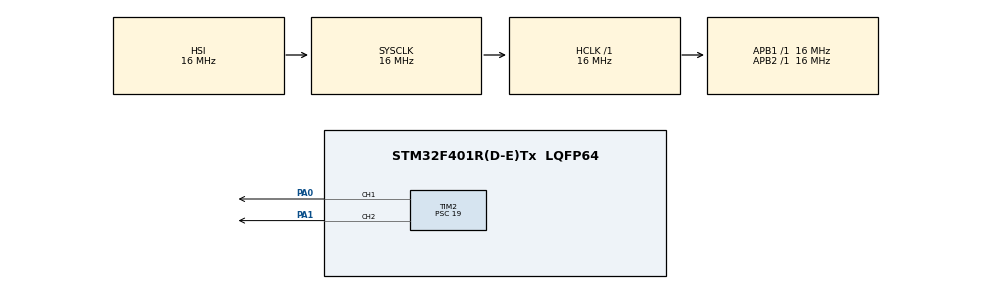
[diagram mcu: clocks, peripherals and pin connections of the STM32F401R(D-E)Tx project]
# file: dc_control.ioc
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Mcu.Family=STM32F4
Mcu.Name=STM32F401R(D-E)Tx
Mcu.Package=LQFP64
NVIC.PriorityGroup=NVIC_PRIORITYGROUP_4
NVIC.TIM2_IRQn=true\:0\:0\:false\:false\:true\:true\:true
PA0-WKUP.Signal=S_TIM2_CH1_ETR
PA1.Signal=S_TIM2_CH2
ProjectManager.HeapSize=0x200
ProjectManager.StackSize=0x400
ProjectManager.TargetToolchain=STM32CubeIDE
RCC.AHBFreq_Value=16000000
RCC.APB1Freq_Value=16000000
RCC.APB2Freq_Value=16000000
RCC.CortexFreq_Value=16000000
RCC.HSE_VALUE=25000000
RCC.HSI_VALUE=16000000
RCC.LSE_VALUE=32768
RCC.SYSCLKFreq_VALUE=16000000
RCC.VCOOutputFreq_Value=192000000
SH.S_TIM2_CH1_ETR.0=TIM2_CH1,PWM Generation1 CH1
SH.S_TIM2_CH2.0=TIM2_CH2,PWM Generation2 CH2
TIM2.Channel-PWM\ Generation1\ CH1=TIM_CHANNEL_1
TIM2.Channel-PWM\ Generation2\ CH2=TIM_CHANNEL_2
TIM2.Period=1000
TIM2.Prescaler=19
TIM2.Pulse-PWM\ Generation1\ CH1=500
TIM2.Pulse-PWM\ Generation2\ CH2=500
VP_TIM2_VS_ClockSourceINT.Mode=Internal
board=custom

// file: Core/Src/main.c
/* USER CODE BEGIN Header */
/**
  ******************************************************************************
  * @file           : main.c
  * @brief          : Main program body
  ******************************************************************************
  * @attention
  *
  * <h2><center>&copy; Copyright (c) 2021 STMicroelectronics.
  * All rights reserved.</center></h2>
  *
  * This software component is licensed by ST under BSD 3-Clause license,
  * the "License"; You may not use this file except in compliance with the
  * License. You may obtain a copy of the License at:
  *                        opensource.org/licenses/BSD-3-Clause
  *
  ******************************************************************************
  */
/* USER CODE END Header */
#include "main.h"

TIM_HandleTypeDef htim2;

void SystemClock_Config(void);
static void MX_GPIO_Init(void);
static void MX_TIM2_Init(void);

int main(void)
{

  /* MCU Configuration--------------------------------------------------------*/

  /* Reset of all peripherals, Initializes the Flash interface and the Systick. */
  HAL_Init();

  /* Configure the system clock */
  SystemClock_Config();

  /* Initialize all configured peripherals */
  MX_GPIO_Init();
  MX_TIM2_Init();
  /* USER CODE BEGIN 2 */
  HAL_TIM_Base_Start(&htim2);
  HAL_TIM_PWM_Start(&htim2,TIM_CHANNEL_1);  //PB0 Start pwm second motor 100% duty cycle
  HAL_TIM_PWM_Start(&htim2,TIM_CHANNEL_2);
  __HAL_TIM_SET_COMPARE(&htim2,TIM_CHANNEL_2,0);
  __HAL_TIM_SET_COMPARE(&htim2,TIM_CHANNEL_1,0);
  HAL_Delay(3000);
//  __HAL_TIM_SET_COMPARE(&htim2,TIM_CHANNEL_1,500);
//  HAL_Delay(3000);
//   /* USER CODE END 2 */
//   HAL_Delay(3000);
//   HAL_TIM_PWM_Stop(&htim2,TIM_CHANNEL_1);
//   __HAL_TIM_SET_COMPARE(&htim2,TIM_CHANNEL_1,500); //Second motor 75% voltage
//   HAL_Delay(3000);
//   HAL_TIM_PWM_Start(&htim2,TIM_CHANNEL_2);
//   HAL_Delay(3000);
//   __HAL_TIM_SET_COMPARE(&htim2,TIM_CHANNEL_2,500);
   //__HAL_TIM_SET_COMPARE(&htim3,TIM_CHANNEL_4,75);
  /* USER CODE END 2 */
 // int i = 100 ;
  /* Infinite loop */
  /* USER CODE BEGIN WHILE */
  while (1)
  {
	  __HAL_TIM_SET_COMPARE(&htim2,TIM_CHANNEL_1,500);
	  HAL_Delay(3000);
	  __HAL_TIM_SET_COMPARE(&htim2,TIM_CHANNEL_1,0);
	  __HAL_TIM_SET_COMPARE(&htim2,TIM_CHANNEL_2,500);
	  HAL_Delay(3000);
	  __HAL_TIM_SET_COMPARE(&htim2,TIM_CHANNEL_2,0);
    /* USER CODE END WHILE */

  }
}

void SystemClock_Config(void)
{
  RCC_OscInitTypeDef RCC_OscInitStruct = {0};
  RCC_ClkInitTypeDef RCC_ClkInitStruct = {0};

  /** Configure the main internal regulator output voltage
  */
  __HAL_RCC_PWR_CLK_ENABLE();
  __HAL_PWR_VOLTAGESCALING_CONFIG(PWR_REGULATOR_VOLTAGE_SCALE2);
  /** Initializes the RCC Oscillators according to the specified parameters
  * in the RCC_OscInitTypeDef structure.
  */
  RCC_OscInitStruct.OscillatorType = RCC_OSCILLATORTYPE_HSI;
  RCC_OscInitStruct.HSIState = RCC_HSI_ON;
  RCC_OscInitStruct.HSICalibrationValue = RCC_HSICALIBRATION_DEFAULT;
  RCC_OscInitStruct.PLL.PLLState = RCC_PLL_NONE;
  if (HAL_RCC_OscConfig(&RCC_OscInitStruct) != HAL_OK)
  {
    Error_Handler();
  }
  /** Initializes the CPU, AHB and APB buses clocks
  */
  RCC_ClkInitStruct.ClockType = RCC_CLOCKTYPE_HCLK|RCC_CLOCKTYPE_SYSCLK
                              |RCC_CLOCKTYPE_PCLK1|RCC_CLOCKTYPE_PCLK2;
  RCC_ClkInitStruct.SYSCLKSource = RCC_SYSCLKSOURCE_HSI;
  RCC_ClkInitStruct.AHBCLKDivider = RCC_SYSCLK_DIV1;
  RCC_ClkInitStruct.APB1CLKDivider = RCC_HCLK_DIV1;
  RCC_ClkInitStruct.APB2CLKDivider = RCC_HCLK_DIV1;

  if (HAL_RCC_ClockConfig(&RCC_ClkInitStruct, FLASH_LATENCY_0) != HAL_OK)
  {
    Error_Handler();
  }
}

static void MX_TIM2_Init(void)
{

  TIM_ClockConfigTypeDef sClockSourceConfig = {0};
  TIM_MasterConfigTypeDef sMasterConfig = {0};
  TIM_OC_InitTypeDef sConfigOC = {0};

  htim2.Instance = TIM2;
  htim2.Init.Prescaler = 19;
  htim2.Init.CounterMode = TIM_COUNTERMODE_UP;
  htim2.Init.Period = 1000;
  htim2.Init.ClockDivision = TIM_CLOCKDIVISION_DIV1;
  htim2.Init.AutoReloadPreload = TIM_AUTORELOAD_PRELOAD_DISABLE;
  if (HAL_TIM_Base_Init(&htim2) != HAL_OK)
  {
    Error_Handler();
  }
  sClockSourceConfig.ClockSource = TIM_CLOCKSOURCE_INTERNAL;
  if (HAL_TIM_ConfigClockSource(&htim2, &sClockSourceConfig) != HAL_OK)
  {
    Error_Handler();
  }
  if (HAL_TIM_PWM_Init(&htim2) != HAL_OK)
  {
    Error_Handler();
  }
  sMasterConfig.MasterOutputTrigger = TIM_TRGO_RESET;
  sMasterConfig.MasterSlaveMode = TIM_MASTERSLAVEMODE_DISABLE;
  if (HAL_TIMEx_MasterConfigSynchronization(&htim2, &sMasterConfig) != HAL_OK)
  {
    Error_Handler();
  }
  sConfigOC.OCMode = TIM_OCMODE_PWM1;
  sConfigOC.Pulse = 500;
  sConfigOC.OCPolarity = TIM_OCPOLARITY_HIGH;
  sConfigOC.OCFastMode = TIM_OCFAST_DISABLE;
  if (HAL_TIM_PWM_ConfigChannel(&htim2, &sConfigOC, TIM_CHANNEL_1) != HAL_OK)
  {
    Error_Handler();
  }
  if (HAL_TIM_PWM_ConfigChannel(&htim2, &sConfigOC, TIM_CHANNEL_2) != HAL_OK)
  {
    Error_Handler();
  }
  HAL_TIM_MspPostInit(&htim2);

}

static void MX_GPIO_Init(void)
{

  /* GPIO Ports Clock Enable */
  __HAL_RCC_GPIOA_CLK_ENABLE();

}

void Error_Handler(void)
{
  __disable_irq();
  while (1)
  {
  }
}

/************************ (C) COPYRIGHT STMicroelectronics *****END OF FILE****/
